# GD32M53x register map
File version: 1.0
CPU: CM33 r2p1, little endian, MPU, FPU, DSP, 4 interrupt priority bits
Registers are 32-bit, read-write, reset 0x0 unless marked. A register's access mark holds for its fields unless they carry their own. Offsets are from the block's base; [hi:lo] are bit positions; {n}, {i} and the like mark numbered series; 'fields as' and 'values as' point back to an identical list.

## DMAMUX — DMAMUX controller
Base 0x40020800
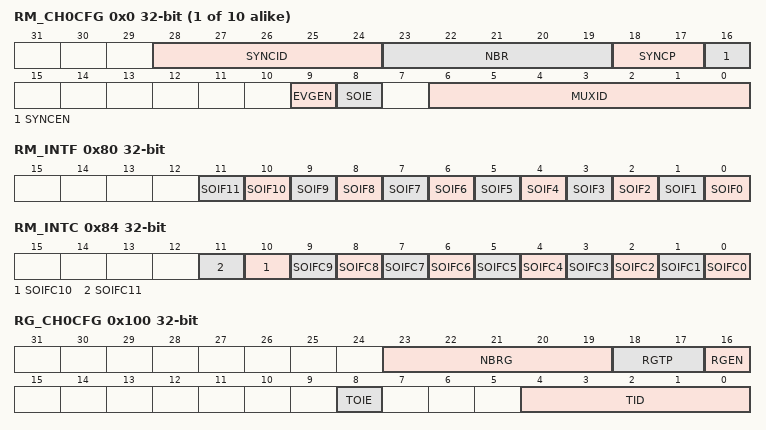
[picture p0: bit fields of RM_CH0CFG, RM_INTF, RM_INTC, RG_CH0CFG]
{0x0+4i} RM_CH{i}CFG (i=0..9) — Request multiplexer channel x configuration register
  [28:24] SYNCID — Synchronization input identification
  [23:19] NBR — Number of DMA requests to forward
  [18:17] SYNCP — Synchronization input polarity
  [16] SYNCEN — Synchronization enable
  [9] EVGEN — Event generation enable
  [8] SOIE — Synchronization overrun interrupt enable
  [6:0] MUXID — Multiplexer input identification
0x80 RM_INTF ro — Request multiplexer channel interrupt flag register
  [n] SOIF{n} (n=0..11) — Synchronization overrun event flag of request multiplexer channel {n}
0x84 RM_INTC wo — Request multiplexer channel interrupt flag clear register
  [n] SOIFC{n} (n=0..11) — Clear bit for synchronization overrun event flag of request multiplexer channel {n}
0x100 RG_CH0CFG — Request generator channel x configuration register
  [23:19] NBRG — Number of DMA requests to be generated
  [18:17] RGTP — DMA request generator trigger polarity
  [16] RGEN — DMA request generator channel x enable
  [8] TOIE — Trigger overrun interrupt enable
  [4:0] TID — Trigger input identification
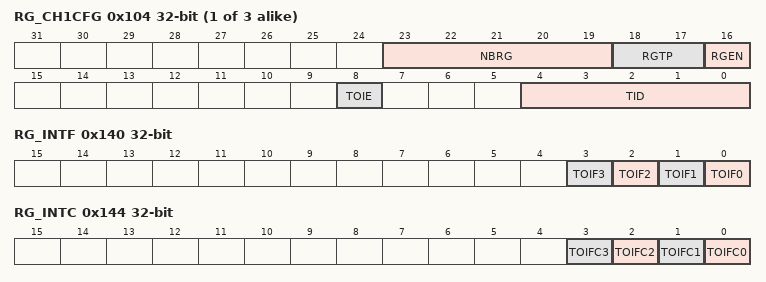
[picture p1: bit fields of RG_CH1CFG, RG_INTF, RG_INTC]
{0x100+4i} RG_CH{i}CFG (i=1..3) — Request generator channel {i} configuration register
  fields as RG_CH0CFG
0x140 RG_INTF ro — Request generator interrupt flag register
  [n] TOIF{n} (n=0..3) — Trigger overrun event flag of request generator channel {n}
0x144 RG_INTC ro — Rquest generator interrupt flag clear register
  [n] TOIFC{n} (n=0..3) — Clear bit for trigger overrun event flag of request generator channel {n}

## EXTI — External interrupt/event controller
Base 0x40010400
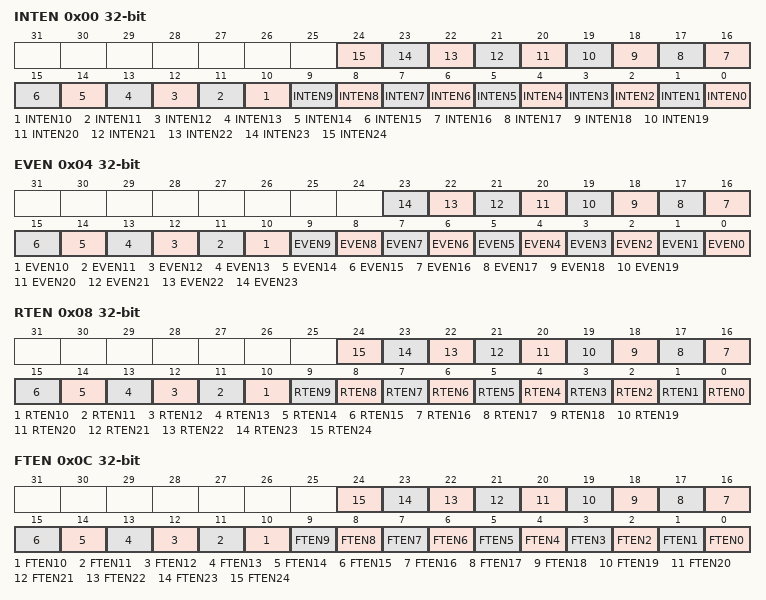
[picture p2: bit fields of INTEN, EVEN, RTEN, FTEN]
0x00 INTEN — Interrupt enable register (EXTI_INTEN)
  [n] INTEN{n} (n=0..24) — Enable Interrupt on line {n}
0x04 EVEN — Event enable register (EXTI_EVEN)
  [n] EVEN{n} (n=0..23) — Enable Event on line {n}
0x08 RTEN — Rising Edge Trigger Enable register (EXTI_RTEN)
  [n] RTEN{n} (n=0..24) — Rising edge trigger enable of line {n}
0x0C FTEN — Falling Egde Trigger Enable register (EXTI_FTEN)
  [n] FTEN{n} (n=0..24) — Falling edge trigger enable of line {n}
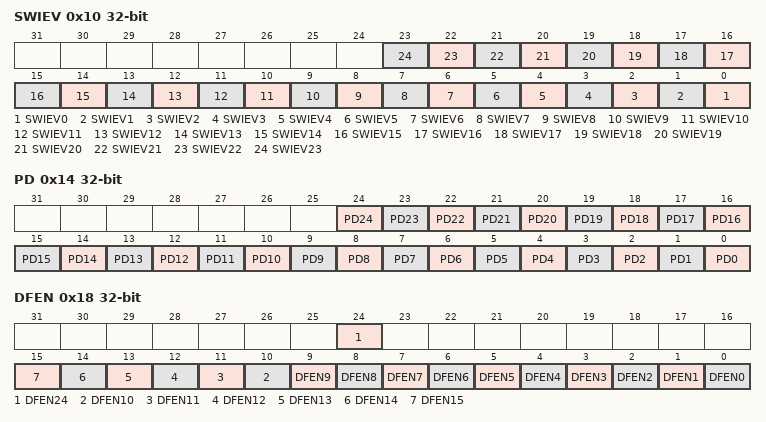
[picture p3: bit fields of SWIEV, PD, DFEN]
0x10 SWIEV — Software interrupt event register (EXTI_SWIEV)
  [n] SWIEV{n} (n=0..23) — Interrupt/Event software trigger on line {n}
0x14 PD — Pending register (EXTI_PD)
  [n] PD{n} (n=0..24) — Interrupt pending status of line {n}
0x18 DFEN — Digital filter enable register (EXTI_DFEN)
  [24] DFEN24 — Digital filter enable of line 24
  [n] DFEN{n} (n=0..15) — Digital filter enable of line {n}
0x1C SCS — Sampling clock select register (EXTI_SCS)
  [1:0] SCS — Select the sampling clock

## FWDGT — free watchdog timer
Base 0x40003000
0x00 CTL wo — Control register
  [15:0] CMD — Key value
0x04 PSC — Prescaler register
  [2:0] PSC — Free watchdog timer prescaler selection
0x08 RLD reset 0xFFF — Reload register
  [11:0] RLD — Free watchdog timer counter reload value
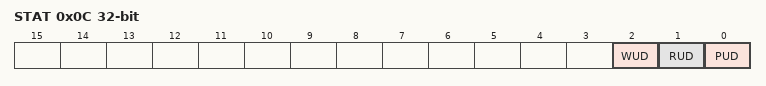
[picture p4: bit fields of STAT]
0x0C STAT ro — Status register
  [2] WUD — Watchdog counter window value update
  [1] RUD — Free watchdog timer counter reload value update
  [0] PUD — Free watchdog timer prescaler value update
0x10 WND reset 0xFFF — Window register
  [11:0] WND — Watchdog counter window value

## GPIOA — General-purpose I/Os
Base 0x48000000
Same registers: GPIOB 0x48000400, GPIOC 0x48000800, GPIOD 0x48000C00, GPIOE 0x48001000, GPIOF 0x48001400, GPIOG 0x48001800
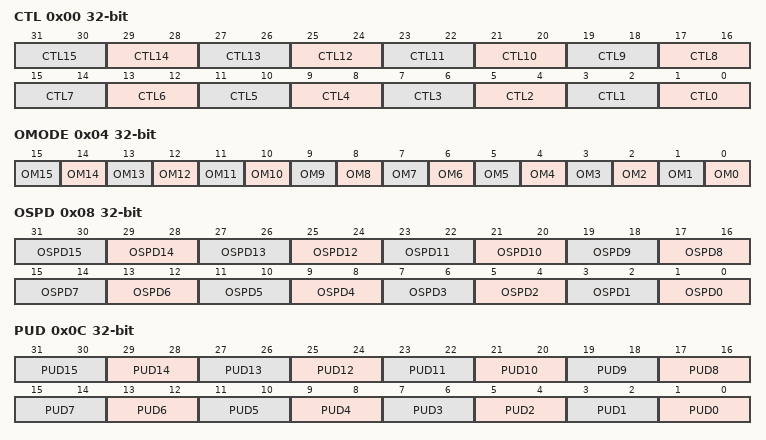
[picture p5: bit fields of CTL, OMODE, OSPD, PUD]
0x00 CTL — GPIO port control register
  [2n+1:2n] CTL{n} (n=0..15) — Port x configuration bits (y = 0..15)
0x04 OMODE — GPIO port output type register
  [n] OM{n} (n=0..15) — Port x configuration bit {n}
0x08 OSPD — GPIO port output speed register
  [2n+1:2n] OSPD{n} (n=0..15) — Port x configuration bits (y = 0..15)
0x0C PUD — GPIO port pull-up/pull-down register
  [2n+1:2n] PUD{n} (n=0..15) — Port x configuration bits (y = 0..15)
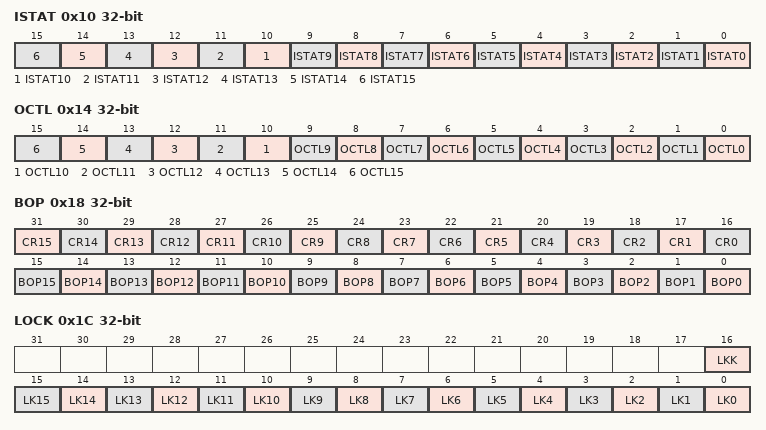
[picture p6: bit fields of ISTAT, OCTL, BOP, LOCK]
0x10 ISTAT ro — GPIO port input data register
  [n] ISTAT{n} (n=0..15) — Port input data (y = 0..15)
0x14 OCTL — GPIO port output data register
  [n] OCTL{n} (n=0..15) — Port output data (y = 0..15)
0x18 BOP wo — GPIO port bit set/resetregister
  [n+16] CR{n} (n=1..15) — Port x reset bit y (y = 0..15)
  [16] CR0 — Port x reset bit y (y= 0..15)
  [n] BOP{n} (n=0..15) — Port x set bit y (y= 0..15)
0x1C LOCK — GPIO port configuration lock register
  [16] LKK — Port x lock bit y
  [15] LK15 — Port x lock bit y (y=0..15)
  [14] LK14 — Port x lock bit y (y= 0..15)
  [13] LK13 — Port x lock bit y (y=0..15)
  [n] LK{n} (n=0..12) — Port x lock bit y (y= 0..15)
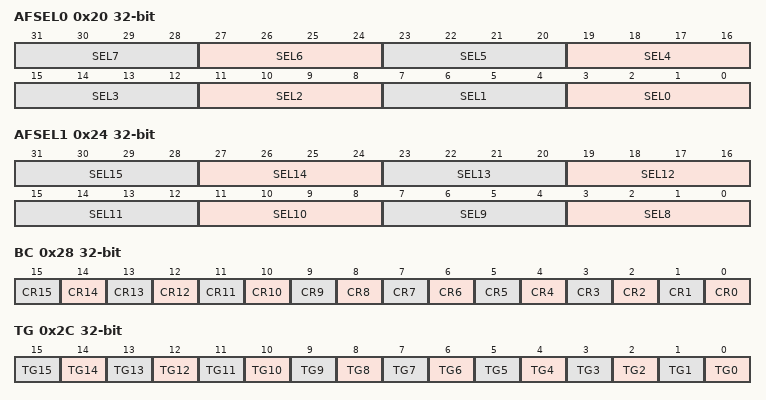
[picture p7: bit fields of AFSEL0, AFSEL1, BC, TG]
0x20 AFSEL0 — GPIO alternate function low register
  [4n+3:4n] SEL{n} (n=0..7) — Alternate function selection for port x bit y (y = 0..7)
0x24 AFSEL1 — GPIO alternate function register 1
  [4n-29:4n-32] SEL{n} (n=8..15) — Alternate function selection for port x bit y (y = 8..15)
0x28 BC wo — Port bit reset register
  [n] CR{n} (n=0..15) — Port cleat bit
0x2C TG wo — Port bit toggle register
  [n] TG{n} (n=0..15) — Port toggle bit
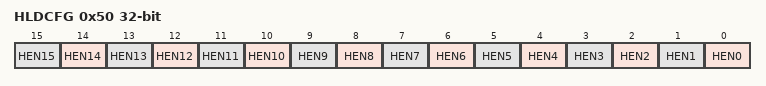
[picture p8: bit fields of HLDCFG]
0x50 HLDCFG wo — Pin level hold config register
  [n] HEN{n} (n=0..15) — Pin level hold enable bit

## GPION — General-purpose I/Os
Base 0x48004000
Registers as GPIOA; these are added or differ:
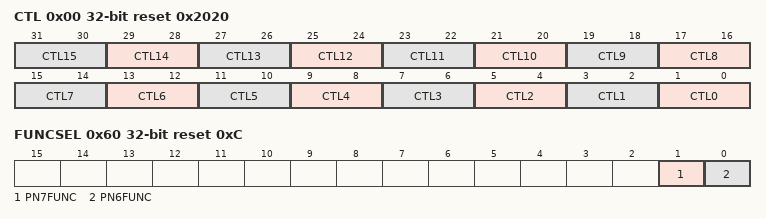
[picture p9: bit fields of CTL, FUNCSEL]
0x00 CTL reset 0x2020 — GPIO port control register
  [2n+1:2n] CTL{n} (n=0..15) — Port x configuration bits (y = 0..15)
0x60 FUNCSEL reset 0xC — Pin function select register
  [1] PN7FUNC — PN7 function select bit
  [0] PN6FUNC — PN6 function select bit
0x64 HLDCTL wo — Pin level hold control register
  [0] HLDUPD — Pin level held updata bit
